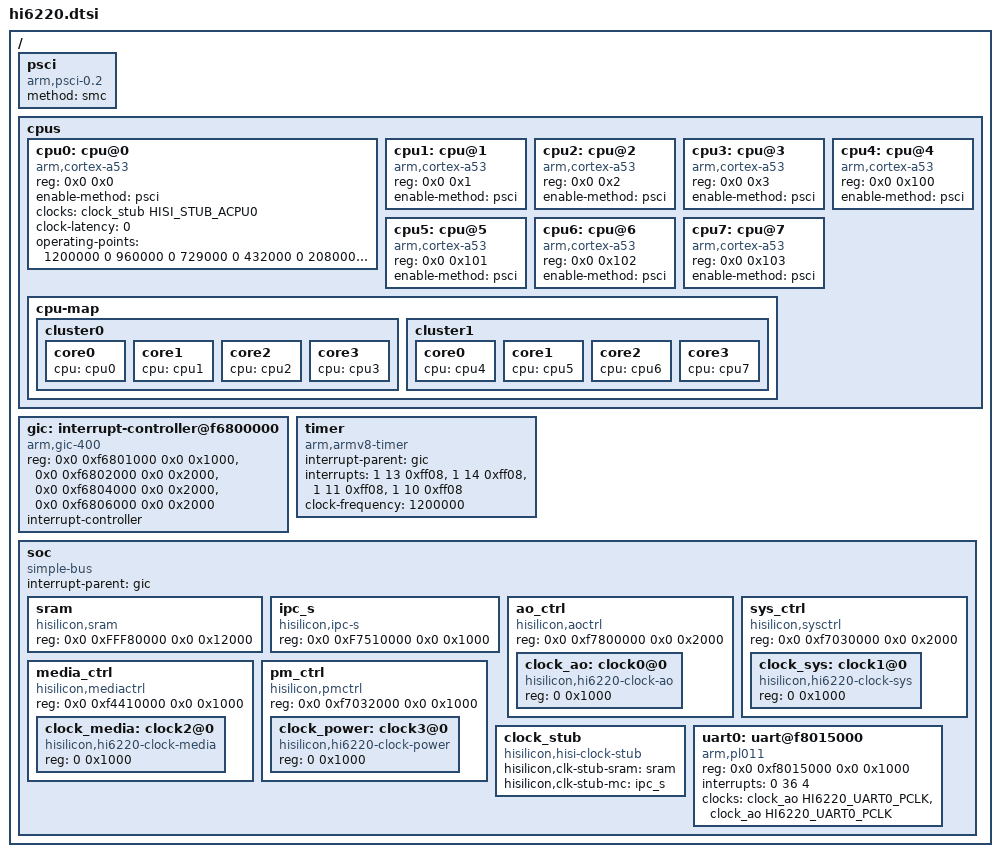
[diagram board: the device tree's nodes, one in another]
/*
 * dts file for Hisilicon Hi6220 SoC
 *
 * Copyright (C) 2015, Hisilicon Ltd.
 */

#include <dt-bindings/clock/hi6220-clock.h>

/ {
	psci {
		compatible = "arm,psci-0.2";
		method = "smc";
	};

	cpus {
		#address-cells = <2>;
		#size-cells = <0>;

		cpu0: cpu@0 {
			compatible = "arm,cortex-a53", "arm,armv8";
			device_type = "cpu";
			reg = <0x0 0x0>;
			enable-method = "psci";
			clocks = <&clock_stub HISI_STUB_ACPU0>;
			clock-latency = <0>;
			operating-points = <
				/* kHz */
				1200000  0
				960000   0
				729000   0
				432000   0
				208000   0
			>;
			#cooling-cells = <2>; /* min followed by max */
		};

		cpu1: cpu@1 {
			compatible = "arm,cortex-a53", "arm,armv8";
			device_type = "cpu";
			reg = <0x0 0x1>;
			enable-method = "psci";
		};

		cpu2: cpu@2 {
			compatible = "arm,cortex-a53", "arm,armv8";
			device_type = "cpu";
			reg = <0x0 0x2>;
			enable-method = "psci";
		};

		cpu3: cpu@3 {
			compatible = "arm,cortex-a53", "arm,armv8";
			device_type = "cpu";
			reg = <0x0 0x3>;
			enable-method = "psci";
		};

		cpu4: cpu@4 {
			compatible = "arm,cortex-a53", "arm,armv8";
			device_type = "cpu";
			reg = <0x0 0x100>;
			enable-method = "psci";
		};

		cpu5: cpu@5 {
			compatible = "arm,cortex-a53", "arm,armv8";
			device_type = "cpu";
			reg = <0x0 0x101>;
			enable-method = "psci";
		};

		cpu6: cpu@6 {
			compatible = "arm,cortex-a53", "arm,armv8";
			device_type = "cpu";
			reg = <0x0 0x102>;
			enable-method = "psci";
		};

		cpu7: cpu@7 {
			compatible = "arm,cortex-a53", "arm,armv8";
			device_type = "cpu";
			reg = <0x0 0x103>;
			enable-method = "psci";
		};

		cpu-map {
			cluster0 {
				core0 {
					cpu = <&cpu0>;
				};
				core1 {
					cpu = <&cpu1>;
				};
				core2 {
					cpu = <&cpu2>;
				};
				core3 {
					cpu = <&cpu3>;
				};
			};
			cluster1 {
				core0 {
					cpu = <&cpu4>;
				};
				core1 {
					cpu = <&cpu5>;
				};
				core2 {
					cpu = <&cpu6>;
				};
				core3 {
					cpu = <&cpu7>;
				};
			};
		};
	};

	gic: interrupt-controller@f6800000 {
		compatible = "arm,gic-400", "arm,cortex-a15-gic";
		reg = <0x0 0xf6801000 0x0 0x1000>, /* GICD */
		      <0x0 0xf6802000 0x0 0x2000>, /* GICC */
		      <0x0 0xf6804000 0x0 0x2000>, /* GICH */
		      <0x0 0xf6806000 0x0 0x2000>; /* GICV */
		#interrupt-cells = <3>;
		#address-cells = <0>;
		interrupt-controller;
	};


	timer {
		compatible = "arm,armv8-timer";
		interrupt-parent = <&gic>;
		interrupts = <1 13 0xff08>,
			     <1 14 0xff08>,
			     <1 11 0xff08>,
			     <1 10 0xff08>;
		clock-frequency = <1200000>;
	};

	soc {
		compatible = "simple-bus";
		#address-cells = <2>;
		#size-cells = <2>;
		interrupt-parent = <&gic>;
		ranges;

		sram: sram {
			compatible = "hisilicon,sram", "syscon";
			reg = <0x0 0xFFF80000 0x0 0x12000>;
		};

		ipc_s: ipc_s {
			compatible = "hisilicon,ipc-s", "syscon";
			reg = <0x0 0xF7510000 0x0 0x1000>;
		};

		ao_ctrl: ao_ctrl {
			compatible = "hisilicon,aoctrl", "syscon";
			#address-cells = <1>;
			#size-cells = <1>;
			reg = <0x0 0xf7800000 0x0 0x2000>;
			ranges = <0 0x0 0xf7800000 0x2000>;

			clock_ao: clock0@0 {
				compatible = "hisilicon,hi6220-clock-ao";
				reg = <0 0x1000>;
				#clock-cells = <1>;
			};
		};

		sys_ctrl: sys_ctrl {
			compatible = "hisilicon,sysctrl", "syscon";
			#address-cells = <1>;
			#size-cells = <1>;
			reg = <0x0 0xf7030000 0x0 0x2000>;
			ranges = <0 0x0 0xf7030000 0x2000>;

			clock_sys: clock1@0 {
				compatible = "hisilicon,hi6220-clock-sys";
				reg = <0 0x1000>;
				#clock-cells = <1>;
			};
		};

		media_ctrl: media_ctrl {
			compatible = "hisilicon,mediactrl", "syscon";
			#address-cells = <1>;
			#size-cells = <1>;
			reg = <0x0 0xf4410000 0x0 0x1000>;
			ranges = <0 0x0 0xf4410000 0x1000>;

			clock_media: clock2@0 {
				compatible = "hisilicon,hi6220-clock-media";
				reg = <0 0x1000>;
				#clock-cells = <1>;
			};
		};

		pm_ctrl: pm_ctrl {
			compatible = "hisilicon,pmctrl", "syscon";
			#address-cells = <1>;
			#size-cells = <1>;
			reg = <0x0 0xf7032000 0x0 0x1000>;
			ranges = <0 0x0 0xf7032000 0x1000>;

			clock_power: clock3@0 {
				compatible = "hisilicon,hi6220-clock-power";
				reg = <0 0x1000>;
				#clock-cells = <1>;
			};
		};

		clock_stub: clock_stub {
			compatible = "hisilicon,hisi-clock-stub";
			hisilicon,clk-stub-sram = <&sram>;
			hisilicon,clk-stub-mc = <&ipc_s>;
			#clock-cells = <1>;
		};

		uart0: uart@f8015000 {	/* console */
			compatible = "arm,pl011", "arm,primecell";
			reg = <0x0 0xf8015000 0x0 0x1000>;
			interrupts = <0 36 4>;
			clocks = <&clock_ao HI6220_UART0_PCLK>, <&clock_ao HI6220_UART0_PCLK>;
			clock-names = "uartclk", "apb_pclk";
		};
	};
};
